# ATmega2561 register map
Vendor: Atmel; File version: 1.0
CPU: other r0p0, little endian, no MPU, no FPU, 4 interrupt priority bits
Registers are 8-bit, read-write, reset 0x0 unless marked. A register's access mark holds for its fields unless they carry their own. Offsets are from the block's base; [hi:lo] are bit positions; {n}, {i} and the like mark numbered series; 'fields as' and 'values as' point back to an identical list.

## EEPROM
Base 0x0080003F
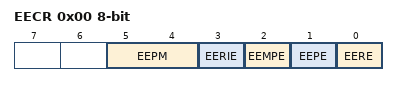
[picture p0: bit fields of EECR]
0x00 EECR — EEPROM Control Register
  [5:4] EEPM — EEPROM Programming Mode Bits
    0=ERASE_AND_WRITE_IN_ONE_OPERATION; 1=ERASE_ONLY; 2=WRITE_ONLY
  [3] EERIE — EEPROM Ready Interrupt Enable
  [2] EEMPE — EEPROM Master Write Enable
  [1] EEPE — EEPROM Write Enable
  [0] EERE — EEPROM Read Enable
0x01 EEDR — EEPROM Data Register
0x02 EEAR 16-bit (reset mask 0xFF) — EEPROM Address Register Low Bytes

## EXINT — External Interrupts
Base 0x0080003B
0x00 PCIFR — Pin Change Interrupt Flag Register (read-only for debugger)
  [2:0] PCIF — Pin Change Interrupt Flags
0x01 EIFR — External Interrupt Flag Register (read-only for debugger)
  [7:0] INTF — External Interrupt Flags
0x02 EIMSK — External Interrupt Mask Register
  [7:0] INT — External Interrupt Request 7 Enable
0x2D PCICR — Pin Change Interrupt Control Register
  [2:0] PCIE — Pin Change Interrupt Enables
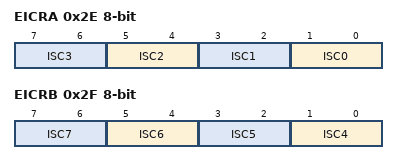
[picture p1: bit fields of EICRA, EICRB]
0x2E EICRA — External Interrupt Control Register A
  [all] fields
    0=LOW_LEVEL_OF_INTX; 1=ANY_LOGICAL_CHANGE_OF_INTX; 2=FALLING_EDGE_OF_INTX; 3=RISING_EDGE_OF_INTX
  [2n+1:2n] ISC{n} (n=0..3) — External Interrupt Sense Control Bit
0x2F EICRB — External Interrupt Control Register B
  [all] fields
    values as the fields of EICRA
  [2n-7:2n-8] ISC{n} (n=4..7) — External Interrupt 7-4 Sense Control Bit
{0x30+i} PCMSK{i} (i=0..2) — Pin Change Mask Register {i}
  [7:0] PCINT — Pin Change Mask interrupt

## JTAG — JTAG Interface
Base 0x00800051
0x00 OCDR — On-Chip Debug Related Register in I/O Memory (write-only for debugger)
0x03 MCUSR — MCU Status Register (read-only for debugger)
  [4] JTRF — JTAG Reset Flag
0x04 MCUCR — MCU Control Register
  [7] JTD — JTAG Interface Disable

## PORTA — I/O Port
Base 0x00800020
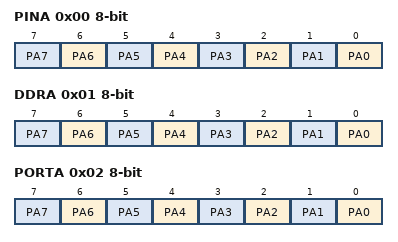
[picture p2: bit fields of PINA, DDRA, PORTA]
0x00 PINA — Port A Input Pins (read-only for debugger)
  [n] PA{n} (n=0..7) — Pin A{n}
0x01 DDRA — Port A Data Direction Register
  [n] PA{n} (n=0..7) — Pin A{n}
0x02 PORTA — Port A Data Register
  [n] PA{n} (n=0..7) — Pin A{n}

## PORTB — I/O Port
Base 0x00800023
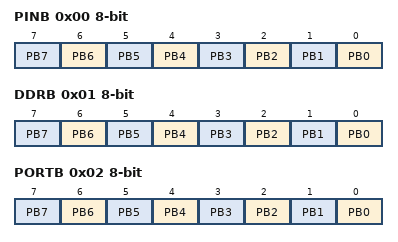
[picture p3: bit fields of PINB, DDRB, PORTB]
0x00 PINB — Port B Input Pins (read-only for debugger)
  [n] PB{n} (n=0..7) — Pin B{n}
0x01 DDRB — Port B Data Direction Register
  [n] PB{n} (n=0..7) — Pin B{n}
0x02 PORTB — Port B Data Register
  [n] PB{n} (n=0..7) — Pin B{n}

## PORTC — I/O Port
Base 0x00800026
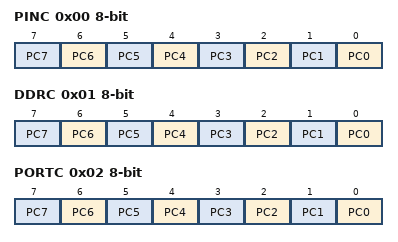
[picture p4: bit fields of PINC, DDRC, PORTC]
0x00 PINC — Port C Input Pins (read-only for debugger)
  [n] PC{n} (n=0..7) — Pin C{n}
0x01 DDRC — Port C Data Direction Register
  [n] PC{n} (n=0..7) — Pin C{n}
0x02 PORTC — Port C Data Register
  [n] PC{n} (n=0..7) — Pin C{n}

## PORTD — I/O Port
Base 0x00800029
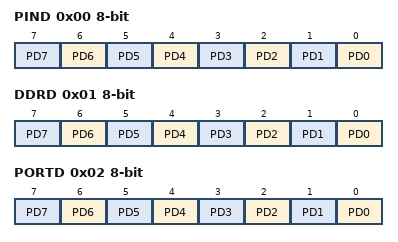
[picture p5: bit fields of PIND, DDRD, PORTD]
0x00 PIND — Port D Input Pins (read-only for debugger)
  [n] PD{n} (n=0..7) — Pin D{n}
0x01 DDRD — Port D Data Direction Register
  [n] PD{n} (n=0..7) — Pin D{n}
0x02 PORTD — Port D Data Register
  [n] PD{n} (n=0..7) — Pin D{n}

## PORTE — I/O Port
Base 0x0080002C
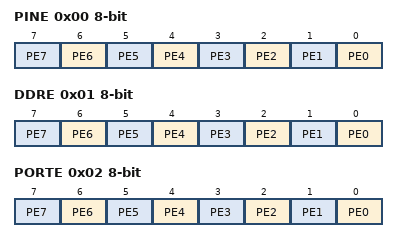
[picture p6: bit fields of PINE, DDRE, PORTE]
0x00 PINE — Input Pins, Port E (read-only for debugger)
  [n] PE{n} (n=0..7) — Pin E{n}
0x01 DDRE — Data Direction Register, Port E
  [n] PE{n} (n=0..7) — Pin E{n}
0x02 PORTE — Data Register, Port E
  [n] PE{n} (n=0..7) — Pin E{n}

## PORTF — I/O Port
Base 0x0080002F
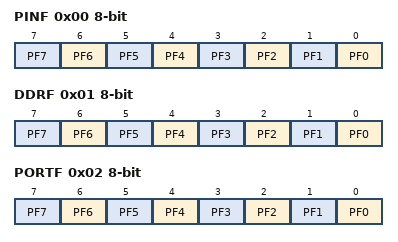
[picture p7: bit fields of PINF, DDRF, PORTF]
0x00 PINF — Input Pins, Port F (read-only for debugger)
  [n] PF{n} (n=0..7) — Pin F{n}
0x01 DDRF — Data Direction Register, Port F
  [n] PF{n} (n=0..7) — Pin F{n}
0x02 PORTF — Data Register, Port F
  [n] PF{n} (n=0..7) — Pin F{n}

## PORTG — I/O Port
Base 0x00800032
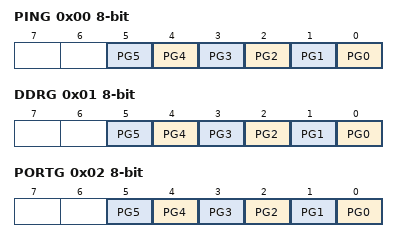
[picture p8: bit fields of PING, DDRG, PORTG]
0x00 PING — Input Pins, Port G
  [n] PG{n} (n=0..5) — Pin G{n}
0x01 DDRG — Data Direction Register, Port G
  [n] PG{n} (n=0..5) — Pin G{n}
0x02 PORTG — Data Register, Port G
  [n] PG{n} (n=0..5) — Pin G{n}
